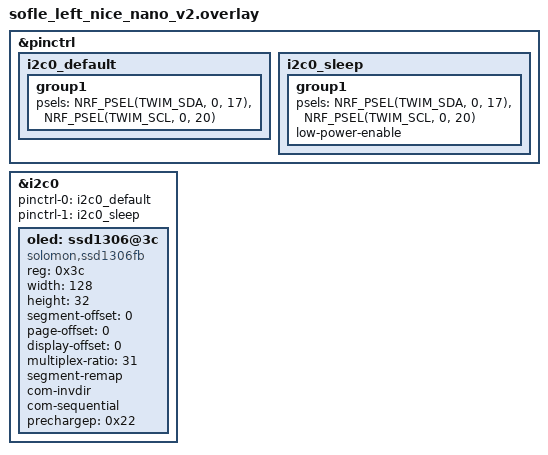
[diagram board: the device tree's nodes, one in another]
/*
 * sofle_left.overlay — Lado ESQUERDO
 *
 * Mantém a OLED funcionando normalmente (SDA P0.17, SCL P0.20).
 * Nenhuma alteração para o trackpad — ele fica só no lado direito.
 */

/* ── Pinctrl para OLED ─────────────────────────────────────────────────── */
&pinctrl {
    i2c0_default: i2c0_default {
        group1 {
            psels = <NRF_PSEL(TWIM_SDA, 0, 17)>,
                    <NRF_PSEL(TWIM_SCL, 0, 20)>;
        };
    };
    i2c0_sleep: i2c0_sleep {
        group1 {
            psels = <NRF_PSEL(TWIM_SDA, 0, 17)>,
                    <NRF_PSEL(TWIM_SCL, 0, 20)>;
            low-power-enable;
        };
    };
};

/* ── I2C para OLED ─────────────────────────────────────────────────────── */
&i2c0 {
    status = "okay";
    pinctrl-0 = <&i2c0_default>;
    pinctrl-1 = <&i2c0_sleep>;
    pinctrl-names = "default", "sleep";

    oled: ssd1306@3c {
        compatible = "solomon,ssd1306fb";
        reg = <0x3c>;
        width = <128>;
        height = <32>;
        segment-offset = <0>;
        page-offset = <0>;
        display-offset = <0>;
        multiplex-ratio = <31>;
        segment-remap;
        com-invdir;
        com-sequential;
        prechargep = <0x22>;
    };
};
